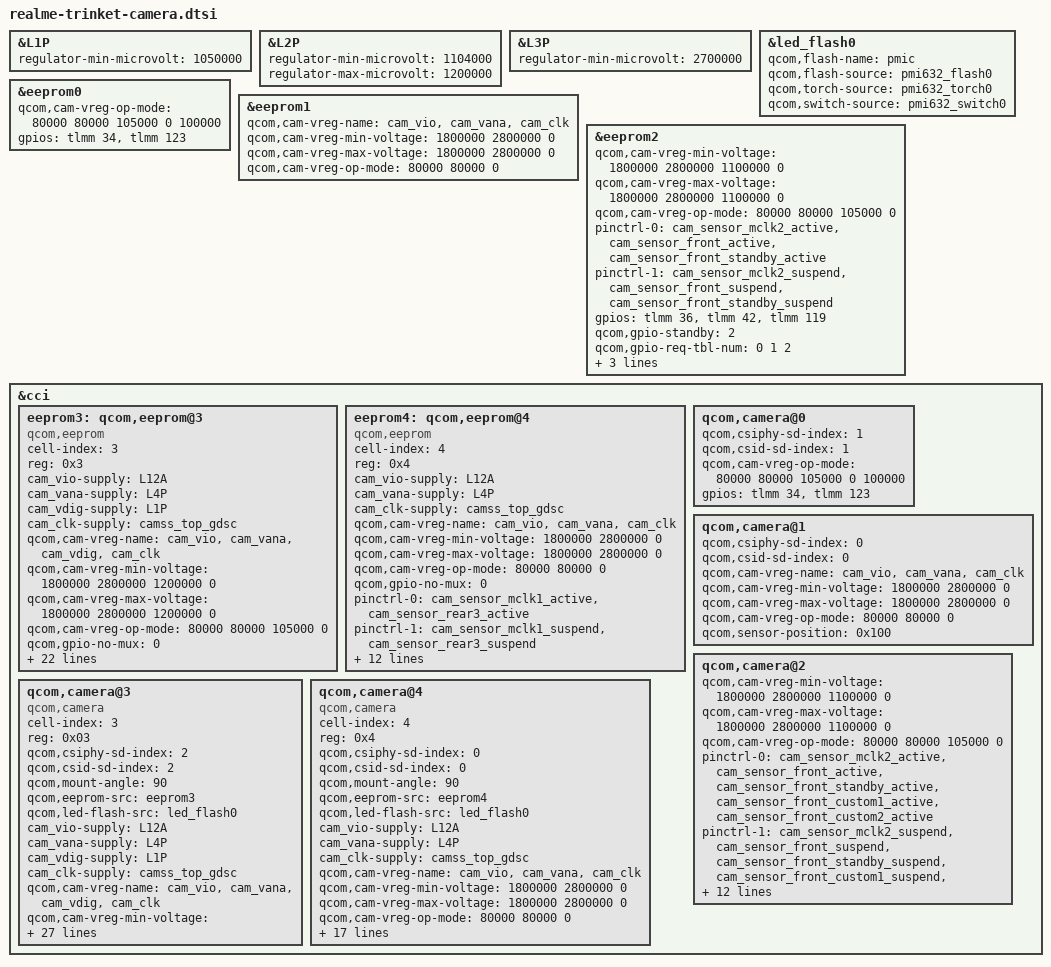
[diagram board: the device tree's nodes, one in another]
&L1P {
	regulator-min-microvolt = <1050000>;
};

&L2P {
	regulator-min-microvolt = <1104000>;
	regulator-max-microvolt = <1200000>;
};

&L3P {
	regulator-min-microvolt = <2700000>;
};

&led_flash0 {
	qcom,flash-name = "pmic";
	qcom,flash-source = <&pmi632_flash0>;
	qcom,torch-source = <&pmi632_torch0 >;
	qcom,switch-source = <&pmi632_switch0 >;
};

&eeprom0 {
	qcom,cam-vreg-op-mode = <80000 80000 105000 0 100000>;
	gpios = <&tlmm 34 0>,
		<&tlmm 123 0>;
};

&eeprom1 {
	/delete-property/ cam_vdig-supply;
	/delete-property/ cam_vaf-supply;

	qcom,cam-vreg-name = "cam_vio", "cam_vana",
			"cam_clk";
	qcom,cam-vreg-min-voltage = <1800000 2800000 0>;
	qcom,cam-vreg-max-voltage = <1800000 2800000 0>;
	qcom,cam-vreg-op-mode = <80000 80000 0>;
};

&eeprom2 {
	qcom,cam-vreg-min-voltage = <1800000 2800000 1100000 0>;
	qcom,cam-vreg-max-voltage = <1800000 2800000 1100000 0>;
	qcom,cam-vreg-op-mode = <80000 80000 105000 0>;
		pinctrl-0 = <&cam_sensor_mclk2_active
				&cam_sensor_front_active
				&cam_sensor_front_standby_active>;
		pinctrl-1 = <&cam_sensor_mclk2_suspend
				&cam_sensor_front_suspend
				&cam_sensor_front_standby_suspend>;
		gpios = <&tlmm 36 0>,
			<&tlmm 42 0>,
			<&tlmm 119 0>;
		qcom,gpio-standby = <2>;
		qcom,gpio-req-tbl-num = <0 1 2>;
		qcom,gpio-req-tbl-flags = <1 0 0>;
		qcom,gpio-req-tbl-label = "CAMIF_MCLK2",
				"CAM_RESET2",
				 "CAM_STANDBY2";
};

&cci {
	eeprom3: qcom,eeprom@3 {
		cell-index = <3>;
		reg = <0x3>;
		compatible = "qcom,eeprom";
		cam_vio-supply = <&L12A>;
		cam_vana-supply = <&L4P>;
		cam_vdig-supply = <&L1P>;
		cam_clk-supply = <&camss_top_gdsc>;
		qcom,cam-vreg-name = "cam_vio", "cam_vana", "cam_vdig",
				"cam_clk";
		qcom,cam-vreg-min-voltage = <1800000 2800000 1200000 0>;
		qcom,cam-vreg-max-voltage = <1800000 2800000 1200000 0>;
		qcom,cam-vreg-op-mode = <80000 80000 105000 0>;
		qcom,gpio-no-mux = <0>;
		pinctrl-names = "cam_default", "cam_suspend";
		pinctrl-0 = <&cam_sensor_mclk3_active
				 &cam_sensor_front2_active
				 &cam_sensor_front_custom1_active
				 &cam_sensor_front_custom2_active>;
		pinctrl-1 = <&cam_sensor_mclk3_suspend
				 &cam_sensor_front2_suspend
				 &cam_sensor_front_custom1_suspend
				 &cam_sensor_front_custom2_suspend>;
		gpios = <&tlmm 44 0>,
			<&tlmm 41 0>,
			<&tlmm 115 0>,
			<&tlmm 114 0>;
		qcom,gpio-reset = <1>;
		qcom,gpio-custom1= <2>;
		qcom,gpio-custom2= <3>;
		qcom,gpio-req-tbl-num = <0 1 2 3>;
		qcom,gpio-req-tbl-flags = <1 0 0 0>;
		qcom,gpio-req-tbl-label = "CAMIF_MCLK3",
			"CAM_RESET3", "CAM3_CUSTOM1",
			"CAM3_CUSTOM2";
		qcom,sensor-position = <0>;
		qcom,sensor-mode = <0>;
		qcom,cci-master = <1>;
		status = "ok";
		clocks = <&clock_gcc GCC_CAMSS_MCLK3_CLK_SRC>,
		    <&clock_gcc GCC_CAMSS_MCLK3_CLK>;
		clock-names = "cam_src_clk", "cam_clk";
		qcom,clock-rates = <24000000 0>;
	};

	eeprom4: qcom,eeprom@4 {
		cell-index = <4>;
		reg = <0x4>;
		compatible = "qcom,eeprom";
		cam_vio-supply = <&L12A>;
		cam_vana-supply = <&L4P>;
		cam_clk-supply = <&camss_top_gdsc>;
		qcom,cam-vreg-name = "cam_vio", "cam_vana",
				"cam_clk";
		qcom,cam-vreg-min-voltage = <1800000 2800000 0>;
		qcom,cam-vreg-max-voltage = <1800000 2800000 0>;
		qcom,cam-vreg-op-mode = <80000 80000 0>;
		qcom,gpio-no-mux = <0>;
		pinctrl-0 = <&cam_sensor_mclk1_active
				 &cam_sensor_rear3_active>;
		pinctrl-1 = <&cam_sensor_mclk1_suspend
				 &cam_sensor_rear3_suspend>;
		gpios = <&tlmm 35 0>,
			<&tlmm 24 0>;
		qcom,gpio-reset = <1>;
		qcom,gpio-req-tbl-num = <0 1>;
		qcom,gpio-req-tbl-flags = <1 0>;
		qcom,gpio-req-tbl-label = "CAMIF_MCLK1",
					  "CAM_RESET4";
		qcom,sensor-position = <0x100>;
		qcom,sensor-mode = <1>;
		qcom,cci-master = <1>;
		status = "ok";
		clocks = <&clock_gcc GCC_CAMSS_MCLK1_CLK_SRC>,
			<&clock_gcc GCC_CAMSS_MCLK1_CLK>;
		clock-names = "cam_src_clk", "cam_clk";
		qcom,clock-rates = <24000000 0>;
	};

	qcom,camera@0 {
		qcom,csiphy-sd-index = <1>;
		qcom,csid-sd-index = <1>;
		qcom,cam-vreg-op-mode = <80000 80000 105000 0 100000>;
		gpios = <&tlmm 34 0>,
			<&tlmm 123 0>;
	};

	qcom,camera@1 {
		qcom,csiphy-sd-index = <0>;
		qcom,csid-sd-index = <0>;

		/delete-property/ qcom,actuator-src;
		/delete-property/ qcom,led-flash-src;
		/delete-property/ cam_vdig-supply;
		/delete-property/ cam_vaf-supply;

		qcom,cam-vreg-name = "cam_vio", "cam_vana",
				"cam_clk";
		qcom,cam-vreg-min-voltage = <1800000 2800000 0>;
		qcom,cam-vreg-max-voltage = <1800000 2800000 0>;
		qcom,cam-vreg-op-mode = <80000 80000 0>;
		qcom,sensor-position = <0x100>;
	};

	qcom,camera@2 {
		qcom,cam-vreg-min-voltage = <1800000 2800000 1100000 0>;
		qcom,cam-vreg-max-voltage = <1800000 2800000 1100000 0>;
		qcom,cam-vreg-op-mode = <80000 80000 105000 0>;
		pinctrl-0 = <&cam_sensor_mclk2_active
				 &cam_sensor_front_active
				 &cam_sensor_front_standby_active
				 &cam_sensor_front_custom1_active
				 &cam_sensor_front_custom2_active>;
		pinctrl-1 = <&cam_sensor_mclk2_suspend
				 &cam_sensor_front_suspend
				 &cam_sensor_front_standby_suspend
				 &cam_sensor_front_custom1_suspend
				 &cam_sensor_front_custom2_suspend>;
		gpios = <&tlmm 36 0>,
			<&tlmm 42 0>,
			<&tlmm 119 0>,
			<&tlmm 115 0>,
			<&tlmm 114 0>;
		qcom,gpio-standby = <2>;
		qcom,gpio-custom1= <3>;
		qcom,gpio-custom2= <4>;
		qcom,gpio-req-tbl-num = <0 1 2 3 4>;
		qcom,gpio-req-tbl-flags = <1 0 0 0 0>;
		qcom,gpio-req-tbl-label = "CAMIF_MCLK2",
					"CAM_RESET2",
					"CAM_STANDBY2",
					"CAM2_CUSTOM1",
					"CAM2_CUSTOM2";
		qcom,sensor-position = <1>;
	};

	//wide
	qcom,camera@3 {
		cell-index = <3>;
		compatible = "qcom,camera";
		reg = <0x03>;
		qcom,csiphy-sd-index = <2>;
		qcom,csid-sd-index = <2>;
		qcom,mount-angle = <90>;
		qcom,eeprom-src = <&eeprom3>;
		qcom,led-flash-src = <&led_flash0>;
		cam_vio-supply = <&L12A>;
		cam_vana-supply = <&L4P>;
		cam_vdig-supply = <&L1P>;
		cam_clk-supply = <&camss_top_gdsc>;
		qcom,cam-vreg-name = "cam_vio", "cam_vana", "cam_vdig",
				"cam_clk";
		qcom,cam-vreg-min-voltage = <1800000 2800000 1200000 0>;
		qcom,cam-vreg-max-voltage = <1800000 2800000 1200000 0>;
		qcom,cam-vreg-op-mode = <80000 80000 105000 0>;
		qcom,gpio-no-mux = <0>;
		pinctrl-names = "cam_default", "cam_suspend";
		pinctrl-0 = <&cam_sensor_mclk3_active
				 &cam_sensor_front2_active
				 &cam_sensor_front_custom1_active
				 &cam_sensor_front_custom2_active>;
		pinctrl-1 = <&cam_sensor_mclk3_suspend
				 &cam_sensor_front2_suspend
				 &cam_sensor_front_custom1_suspend
				 &cam_sensor_front_custom2_suspend>;
		gpios = <&tlmm 44 0>,
			<&tlmm 41 0>,
			<&tlmm 115 0>,
			<&tlmm 114 0>;
		qcom,gpio-reset = <1>;
		qcom,gpio-custom1= <2>;
		qcom,gpio-custom2= <3>;
		qcom,gpio-req-tbl-num = <0 1 2 3>;
		qcom,gpio-req-tbl-flags = <1 0 0 0>;
		qcom,gpio-req-tbl-label = "CAMIF_MCLK3",
			"CAM_RESET3", "CAM3_CUSTOM1",
			"CAM3_CUSTOM2";
		qcom,sensor-position = <0x100>;
		qcom,sensor-mode = <0>;
		qcom,cci-master = <1>;
		status = "ok";
		clocks = <&clock_gcc GCC_CAMSS_MCLK3_CLK_SRC>,
			<&clock_gcc GCC_CAMSS_MCLK3_CLK>;
		clock-names = "cam_src_clk", "cam_clk";
		qcom,clock-rates = <24000000 0>;
	};

	//Macro distance
	qcom,camera@4 {
		cell-index = <4>;
		compatible = "qcom,camera";
		reg = <0x4>;
		qcom,csiphy-sd-index = <0>;
		qcom,csid-sd-index = <0>;
		qcom,mount-angle = <90>;
		qcom,eeprom-src = <&eeprom4>;
		qcom,led-flash-src = <&led_flash0>;
		cam_vio-supply = <&L12A>;
		cam_vana-supply = <&L4P>;
		cam_clk-supply = <&camss_top_gdsc>;
		qcom,cam-vreg-name = "cam_vio", "cam_vana", /*"cam_vdig",*/
				"cam_clk";
		qcom,cam-vreg-min-voltage = <1800000 2800000 /*1200000*/ 0>;
		qcom,cam-vreg-max-voltage = <1800000 2800000 /*1200000*/ 0>;
		qcom,cam-vreg-op-mode = <80000 80000 /*105000*/ 0>;
		qcom,gpio-no-mux = <0>;
		pinctrl-names = "cam_default", "cam_suspend";
		pinctrl-0 = <&cam_sensor_mclk1_active
				 &cam_sensor_rear3_active>;
		pinctrl-1 = <&cam_sensor_mclk1_suspend
				 &cam_sensor_rear3_suspend>;
		gpios = <&tlmm 35 0>,
			<&tlmm 24 0>;
		qcom,gpio-reset = <1>;
		qcom,gpio-req-tbl-num = <0 1>;
		qcom,gpio-req-tbl-flags = <1 0>;
		qcom,gpio-req-tbl-label = "CAMIF_MCLK1",
					  "CAM_RESET4";
		qcom,sensor-position = <0x100>;
		qcom,sensor-mode = <1>;
		qcom,cci-master = <1>;
		status = "ok";
		clocks = <&clock_gcc GCC_CAMSS_MCLK1_CLK_SRC>,
			<&clock_gcc GCC_CAMSS_MCLK1_CLK>;
		clock-names = "cam_src_clk", "cam_clk";
		qcom,clock-rates = <24000000 0>;
	};
};
